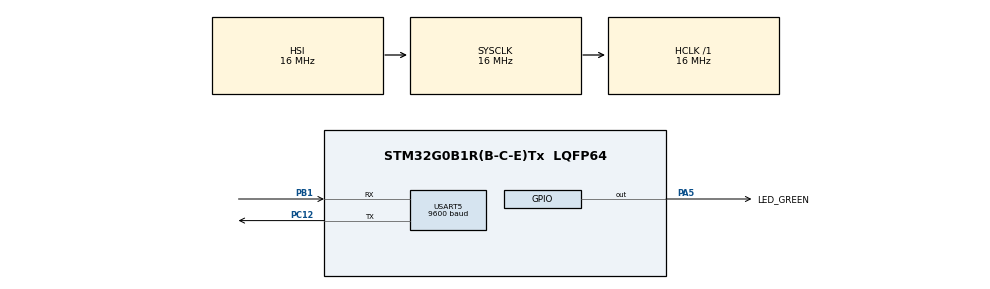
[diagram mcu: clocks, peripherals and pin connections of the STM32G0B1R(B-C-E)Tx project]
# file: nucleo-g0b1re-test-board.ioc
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Dma.Request0=USART5_RX
Dma.Request1=USART5_TX
Dma.USART5_RX.0.Direction=DMA_PERIPH_TO_MEMORY
Dma.USART5_RX.0.EventEnable=DISABLE
Dma.USART5_RX.0.Instance=DMA1_Channel1
Dma.USART5_RX.0.MemDataAlignment=DMA_MDATAALIGN_BYTE
Dma.USART5_RX.0.MemInc=DMA_MINC_ENABLE
Dma.USART5_RX.0.Mode=DMA_NORMAL
Dma.USART5_RX.0.PeriphDataAlignment=DMA_PDATAALIGN_BYTE
Dma.USART5_RX.0.PeriphInc=DMA_PINC_DISABLE
Dma.USART5_RX.0.Polarity=HAL_DMAMUX_REQ_GEN_RISING
Dma.USART5_RX.0.Priority=DMA_PRIORITY_LOW
Dma.USART5_RX.0.RequestNumber=1
Dma.USART5_RX.0.SignalID=NONE
Dma.USART5_RX.0.SyncEnable=DISABLE
Dma.USART5_RX.0.SyncPolarity=HAL_DMAMUX_SYNC_NO_EVENT
Dma.USART5_RX.0.SyncRequestNumber=1
Dma.USART5_RX.0.SyncSignalID=NONE
Dma.USART5_TX.1.Direction=DMA_MEMORY_TO_PERIPH
Dma.USART5_TX.1.EventEnable=DISABLE
Dma.USART5_TX.1.Instance=DMA1_Channel2
Dma.USART5_TX.1.MemDataAlignment=DMA_MDATAALIGN_BYTE
Dma.USART5_TX.1.MemInc=DMA_MINC_ENABLE
Dma.USART5_TX.1.Mode=DMA_NORMAL
Dma.USART5_TX.1.PeriphDataAlignment=DMA_PDATAALIGN_BYTE
Dma.USART5_TX.1.PeriphInc=DMA_PINC_DISABLE
Dma.USART5_TX.1.Polarity=HAL_DMAMUX_REQ_GEN_RISING
Dma.USART5_TX.1.Priority=DMA_PRIORITY_LOW
Dma.USART5_TX.1.RequestNumber=1
Dma.USART5_TX.1.SignalID=NONE
Dma.USART5_TX.1.SyncEnable=DISABLE
Dma.USART5_TX.1.SyncPolarity=HAL_DMAMUX_SYNC_NO_EVENT
Dma.USART5_TX.1.SyncRequestNumber=1
Dma.USART5_TX.1.SyncSignalID=NONE
Mcu.Family=STM32G0
Mcu.Name=STM32G0B1R(B-C-E)Tx
Mcu.Package=LQFP64
NVIC.DMA1_Channel1_IRQn=true\:0\:0\:false\:false\:true\:false\:true\:true
NVIC.DMA1_Channel2_3_IRQn=true\:0\:0\:false\:false\:true\:false\:true\:true
NVIC.USART3_4_5_6_LPUART1_IRQn=true\:0\:0\:false\:false\:true\:true\:true\:true
PA5.GPIO_Label=LED_GREEN
PA5.GPIO_Speed=GPIO_SPEED_FREQ_HIGH
PA5.Signal=GPIO_Output
PB1.Mode=Asynchronous
PB1.Signal=USART5_RX
PC12.Mode=Asynchronous
PC12.Signal=USART5_TX
PC13.Mode=SYS_WakeUp1
PC13.Signal=SYS_WKUP2
PC14-OSC32_IN\ (PC14).Mode=LSE-External-Oscillator
PC14-OSC32_IN\ (PC14).Signal=RCC_OSC32_IN
PC15-OSC32_OUT\ (PC15).Mode=LSE-External-Oscillator
PC15-OSC32_OUT\ (PC15).Signal=RCC_OSC32_OUT
PF0-OSC_IN\ (PF0).GPIO_Label=MCO
PF0-OSC_IN\ (PF0).Mode=HSE-External-Clock-Source
PF0-OSC_IN\ (PF0).Signal=RCC_OSC_IN
ProjectManager.HeapSize=0x200
ProjectManager.StackSize=0x400
ProjectManager.TargetToolchain=STM32CubeIDE
RCC.AHBFreq_Value=16000000
RCC.CortexFreq_Value=16000000
RCC.EXTERNAL_CLOCK_VALUE=12288000
RCC.HCLKFreq_Value=16000000
RCC.HSE_VALUE=8000000
RCC.HSI48_VALUE=48000000
RCC.HSI_VALUE=16000000
RCC.SYSCLKFreq_VALUE=16000000
RCC.USBFreq_Value=48000000
RCC.VCOOutputFreq_Value=128000000
USART5.BaudRate=9600
USART5.OverrunDisableParam=ADVFEATURE_OVERRUN_DISABLE
USART5.VirtualMode-Asynchronous=VM_ASYNC
VP_SYS_VS_DBSignals.Mode=DisableDeadBatterySignals
board=NUCLEO-G0B1RE

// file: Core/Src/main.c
/* USER CODE BEGIN Header */
/**
  ******************************************************************************
  * @file           : main.c
  * @brief          : Main program body
  ******************************************************************************
  * @attention
  *
  * Copyright (c) 2023 STMicroelectronics.
  * All rights reserved.
  *
  * This software is licensed under terms that can be found in the LICENSE file
  * in the root directory of this software component.
  * If no LICENSE file comes with this software, it is provided AS-IS.
  *
  ******************************************************************************
  */
/* USER CODE END Header */
#include "main.h"

/* USER CODE BEGIN Includes */
#include <stdbool.h>
#include <string.h>
#include <customSerial.h>

/* USER CODE END Includes */

UART_HandleTypeDef huart5;
bool isHead = false;

uint8_t headMsg[] = "I'm the head!\n";
uint8_t nonHeadMsg[] = "I'm not the head!\n";

uint32_t curTick = 0;

uint32_t transmitInt = 500;
uint32_t transmitPrev = 0;

uint32_t pulsePrev = 0;

void SystemClock_Config(void);
static void MX_GPIO_Init(void);
static void MX_USART5_UART_Init(void);
void Reconfigure_Tx(void);
/* USER CODE BEGIN PFP */
void sendMessage(void);
void readMessage(void);
bool processMessage(void);
bool identifyHeadDevice();
bool timeoutInterval(uint32_t prev, uint32_t inter);

/* USER CODE END PFP */

int main(void)
{

  /* MCU Configuration--------------------------------------------------------*/

  /* Reset of all peripherals, Initializes the Flash interface and the Systick. */
  HAL_Init();

  /* Configure the system clock */
  SystemClock_Config();

  /* Initialize all configured peripherals */
  MX_GPIO_Init();
  MX_USART5_UART_Init();
  /* USER CODE BEGIN 2 */
  customSerial_Init(&huart5);
  /* USER CODE END 2 */

  /* Infinite loop */
  /* USER CODE BEGIN WHILE */
  // Initial Receive request...
  isHead = identifyHeadDevice();
  readMessage();

  while (1) {
    uint8_t pulseInterval = isHead ? 50 : 100;
    uint8_t* msg = isHead ? headMsg : nonHeadMsg;
    uint8_t size = (isHead ? sizeof(headMsg) : sizeof(nonHeadMsg)) - 1;
    curTick = HAL_GetTick();

    if(timeoutInterval(pulsePrev, pulseInterval)) {
      HAL_GPIO_TogglePin(LED_GREEN_GPIO_Port, LED_GREEN_Pin);
      pulsePrev = curTick;
    }
    if(timeoutInterval(transmitPrev, transmitInt)) {
      HAL_UART_Transmit_IT(&huart5, msg, size);
      transmitPrev = curTick;
    }
  }
  /* USER CODE END 3 */
}

void SystemClock_Config(void)
{
  RCC_OscInitTypeDef RCC_OscInitStruct = {0};
  RCC_ClkInitTypeDef RCC_ClkInitStruct = {0};

  /** Configure the main internal regulator output voltage
  */
  HAL_PWREx_ControlVoltageScaling(PWR_REGULATOR_VOLTAGE_SCALE1);

  /** Initializes the RCC Oscillators according to the specified parameters
  * in the RCC_OscInitTypeDef structure.
  */
  RCC_OscInitStruct.OscillatorType = RCC_OSCILLATORTYPE_HSI;
  RCC_OscInitStruct.HSIState = RCC_HSI_ON;
  RCC_OscInitStruct.HSIDiv = RCC_HSI_DIV1;
  RCC_OscInitStruct.HSICalibrationValue = RCC_HSICALIBRATION_DEFAULT;
  RCC_OscInitStruct.PLL.PLLState = RCC_PLL_NONE;
  if (HAL_RCC_OscConfig(&RCC_OscInitStruct) != HAL_OK)
  {
    Error_Handler();
  }

  /** Initializes the CPU, AHB and APB buses clocks
  */
  RCC_ClkInitStruct.ClockType = RCC_CLOCKTYPE_HCLK|RCC_CLOCKTYPE_SYSCLK
                              |RCC_CLOCKTYPE_PCLK1;
  RCC_ClkInitStruct.SYSCLKSource = RCC_SYSCLKSOURCE_HSI;
  RCC_ClkInitStruct.AHBCLKDivider = RCC_SYSCLK_DIV1;
  RCC_ClkInitStruct.APB1CLKDivider = RCC_HCLK_DIV1;

  if (HAL_RCC_ClockConfig(&RCC_ClkInitStruct, FLASH_LATENCY_0) != HAL_OK)
  {
    Error_Handler();
  }
}

static void MX_USART5_UART_Init(void)
{

  huart5.Instance = USART5;
  huart5.Init.BaudRate = 9600;
  huart5.Init.WordLength = UART_WORDLENGTH_8B;
  huart5.Init.StopBits = UART_STOPBITS_1;
  huart5.Init.Parity = UART_PARITY_NONE;
  huart5.Init.Mode = UART_MODE_TX_RX;
  huart5.Init.HwFlowCtl = UART_HWCONTROL_NONE;
  huart5.Init.OverSampling = UART_OVERSAMPLING_16;
  huart5.Init.OneBitSampling = UART_ONE_BIT_SAMPLE_DISABLE;
  huart5.Init.ClockPrescaler = UART_PRESCALER_DIV1;
  huart5.AdvancedInit.AdvFeatureInit = UART_ADVFEATURE_RXOVERRUNDISABLE_INIT;
  huart5.AdvancedInit.OverrunDisable = UART_ADVFEATURE_OVERRUN_DISABLE;
  if (HAL_UART_Init(&huart5) != HAL_OK)
  {
    Error_Handler();
  }

}

static void MX_GPIO_Init(void)
{
  GPIO_InitTypeDef GPIO_InitStruct = {0};

  /* GPIO Ports Clock Enable */
  __HAL_RCC_GPIOC_CLK_ENABLE();
  __HAL_RCC_GPIOF_CLK_ENABLE();
  __HAL_RCC_GPIOA_CLK_ENABLE();
  __HAL_RCC_GPIOB_CLK_ENABLE();

  /*Configure GPIO pin Output Level */
  HAL_GPIO_WritePin(LED_GREEN_GPIO_Port, LED_GREEN_Pin, GPIO_PIN_RESET);

  /*Configure GPIO pin : LED_GREEN_Pin */
  GPIO_InitStruct.Pin = LED_GREEN_Pin;
  GPIO_InitStruct.Mode = GPIO_MODE_OUTPUT_PP;
  GPIO_InitStruct.Pull = GPIO_NOPULL;
  GPIO_InitStruct.Speed = GPIO_SPEED_FREQ_HIGH;
  HAL_GPIO_Init(LED_GREEN_GPIO_Port, &GPIO_InitStruct);

}

/* USER CODE BEGIN 4 */
void reconfigureUartTxRxGPIO(void) {
  if(HAL_UART_DeInit(&huart5) == HAL_OK) {

    // Initialize the GPIO Pin...
      /*Configure GPIO pin Output Level */
      HAL_GPIO_WritePin(GPIOC, GPIO_PIN_12, GPIO_PIN_RESET);

      GPIO_InitTypeDef GPIO_InitStruct = {0};

      /*Configure GPIO pin : GPIOC_PIN_12 (Tx) */
      GPIO_InitStruct.Pin = GPIO_PIN_12;
      GPIO_InitStruct.Mode = GPIO_MODE_OUTPUT_PP;
      GPIO_InitStruct.Pull = GPIO_NOPULL;
      GPIO_InitStruct.Speed = GPIO_SPEED_FREQ_LOW;
      HAL_GPIO_Init(GPIOC, &GPIO_InitStruct);

      /*Configure GPIO pin : GPIOB_PIN_1 (Rx) */
      GPIO_InitStruct.Pin = GPIO_PIN_1;
      GPIO_InitStruct.Mode = GPIO_MODE_INPUT;
      GPIO_InitStruct.Pull = GPIO_PULLUP;
      GPIO_InitStruct.Speed = GPIO_SPEED_FREQ_LOW;
      HAL_GPIO_Init(GPIOB, &GPIO_InitStruct);
  }

}

bool identifyHeadDevice(void) {

  // 1. Change Tx, Rx so we can control directly...
  reconfigureUartTxRxGPIO();

  // 2. Hold down Tx to let the next node know that there is a link...
  HAL_GPIO_WritePin(GPIOC, GPIO_PIN_12, 0);
  HAL_Delay(5000);

  // 3. Read the Rx to detect that there is a link (Held low)...
  bool detectsLink = false;
  detectsLink = HAL_GPIO_ReadPin(GPIOB, GPIO_PIN_1) == GPIO_PIN_RESET;
  HAL_Delay(5000);

  // Give GPIO pins back to UART again for communication
  MX_USART5_UART_Init();

  // 4. If a link does not exist you are the head...
  return !detectsLink;
}

bool timeoutInterval(uint32_t prev, uint32_t inter) {
  return (curTick - prev >= inter);
}
/* USER CODE END 4 */

void Error_Handler(void)
{
  __disable_irq();
  while (1)
  {
  }
}
